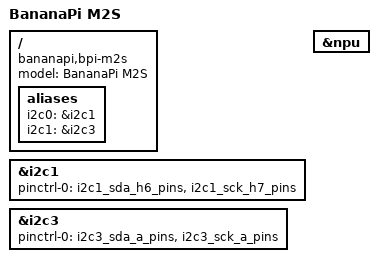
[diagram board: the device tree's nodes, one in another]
/dts-v1/;
#include "meson-g12b-a311d.dtsi"
#include "meson-g12b-bananapi.dtsi"
/ {
	compatible = "bananapi,bpi-m2s", "amlogic,a311d", "amlogic,g12b";
	model = "BananaPi M2S";
	aliases {
		i2c0 = &i2c1;
		i2c1 = &i2c3;
	};
};
&i2c1 {
	status = "okay";
	pinctrl-0 = <&i2c1_sda_h6_pins>, <&i2c1_sck_h7_pins>;
	pinctrl-names = "default";
};
&i2c3 {
	status = "okay";
	pinctrl-0 = <&i2c3_sda_a_pins>, <&i2c3_sck_a_pins>;
	pinctrl-names = "default";
};
&npu {
	status = "okay";
};
